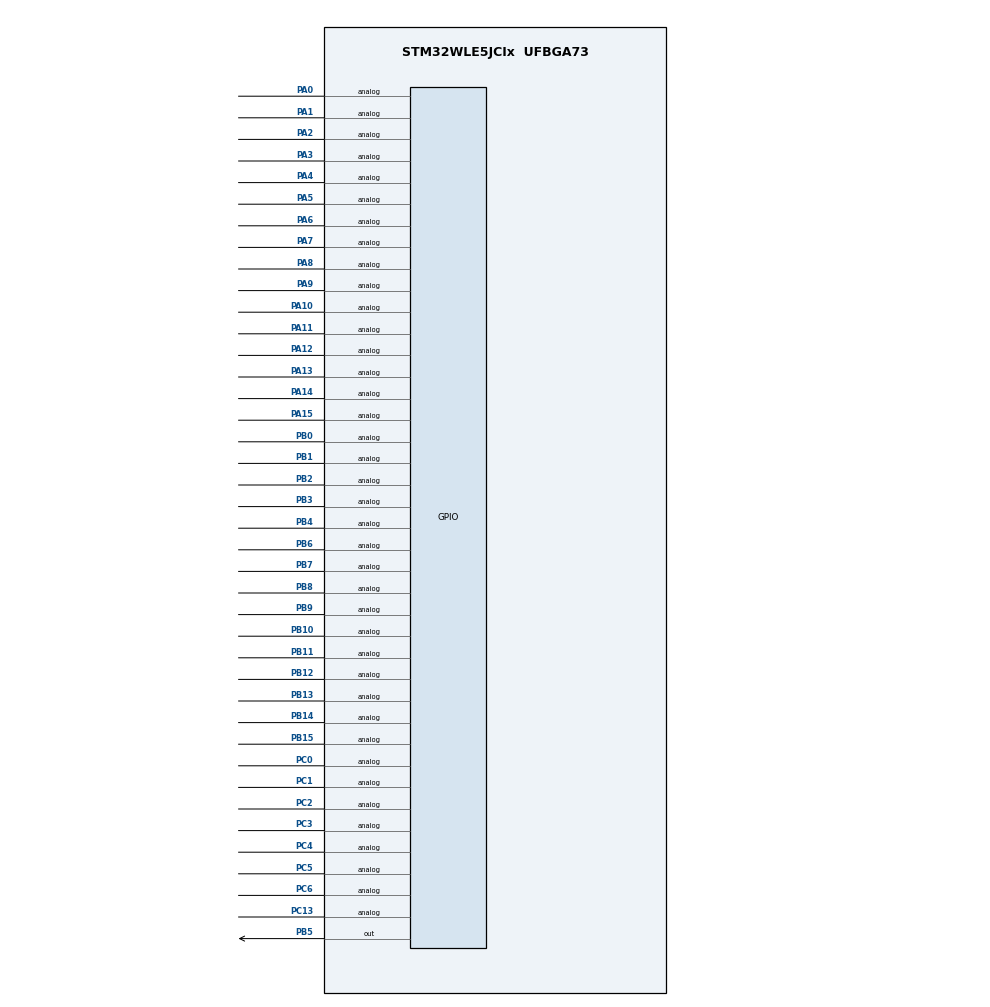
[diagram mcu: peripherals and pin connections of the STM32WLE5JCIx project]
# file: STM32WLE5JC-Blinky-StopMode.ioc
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Mcu.Family=STM32WL
Mcu.Name=STM32WLE5JCIx
Mcu.Package=UFBGA73
NVIC.PriorityGroup=NVIC_PRIORITYGROUP_4
NVIC.RTC_WKUP_IRQn=true\:0\:0\:false\:false\:true\:true\:true
PA0.Signal=GPIO_Analog
PA1.Signal=GPIO_Analog
PA10.Signal=GPIO_Analog
PA11.Signal=GPIO_Analog
PA12.Signal=GPIO_Analog
PA13.Signal=GPIO_Analog
PA14.Signal=GPIO_Analog
PA15.Signal=GPIO_Analog
PA2.Signal=GPIO_Analog
PA3.Signal=GPIO_Analog
PA4.Signal=GPIO_Analog
PA5.Signal=GPIO_Analog
PA6.Signal=GPIO_Analog
PA7.Signal=GPIO_Analog
PA8.Signal=GPIO_Analog
PA9.Signal=GPIO_Analog
PB0-VDD_TCXO.Signal=GPIO_Analog
PB1.Signal=GPIO_Analog
PB10.Signal=GPIO_Analog
PB11.Signal=GPIO_Analog
PB12.Signal=GPIO_Analog
PB13.Signal=GPIO_Analog
PB14.Signal=GPIO_Analog
PB15.Signal=GPIO_Analog
PB2.Signal=GPIO_Analog
PB3.Signal=GPIO_Analog
PB4.Signal=GPIO_Analog
PB5.GPIO_PuPd=GPIO_PULLUP
PB5.Signal=GPIO_Output
PB6.Signal=GPIO_Analog
PB7.Signal=GPIO_Analog
PB8.Signal=GPIO_Analog
PB9.Signal=GPIO_Analog
PC0.Signal=GPIO_Analog
PC1.Signal=GPIO_Analog
PC13.Signal=GPIO_Analog
PC14-OSC32_IN.Mode=LSE-External-Oscillator
PC14-OSC32_IN.Signal=RCC_OSC32_IN
PC15-OSC32_OUT.Mode=LSE-External-Oscillator
PC15-OSC32_OUT.Signal=RCC_OSC32_OUT
PC2.Signal=GPIO_Analog
PC3.Signal=GPIO_Analog
PC4.Signal=GPIO_Analog
PC5.Signal=GPIO_Analog
PC6.Signal=GPIO_Analog
ProjectManager.HeapSize=0x200
ProjectManager.StackSize=0x400
ProjectManager.TargetToolchain=STM32CubeIDE
RCC.AHBFreq_Value=48000000
RCC.APB1Freq_Value=48000000
RCC.APB1TimFreq_Value=48000000
RCC.APB2Freq_Value=48000000
RCC.APB2TimFreq_Value=48000000
RCC.APB3Freq_Value=48000000
RCC.CortexFreq_Value=48000000
RCC.HCLKFreq_Value=48000000
RCC.HSE_VALUE=8000000
RCC.HSI_VALUE=16000000
RCC.LSE_VALUE=32768
RCC.MSIClockRange=RCC_MSIRANGE_11
RCC.RTCClockSelection=RCC_RTCCLKSOURCE_LSE
RCC.SYSCLKFreq_VALUE=48000000
RCC.VCOOutputFreq_Value=384000000
VP_RTC_VS_RTC_Activate.Mode=RTC_Enabled
VP_RTC_VS_RTC_WakeUp_intern.Mode=WakeUp
board=custom

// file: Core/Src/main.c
/* USER CODE BEGIN Header */
/**
  ******************************************************************************
  * @file           : main.c
  * @brief          : Main program body
  ******************************************************************************
  * @attention
  *
  * <h2><center>&copy; Copyright (c) 2021 STMicroelectronics.
  * All rights reserved.</center></h2>
  *
  * This software component is licensed by ST under BSD 3-Clause license,
  * the "License"; You may not use this file except in compliance with the
  * License. You may obtain a copy of the License at:
  *                        opensource.org/licenses/BSD-3-Clause
  *
  ******************************************************************************
  */
/* USER CODE END Header */
#include "main.h"

RTC_HandleTypeDef hrtc;

void SystemClock_Config(void);
static void MX_RTC_Init(void);
static void MX_GPIO_Init(void);

int main(void)
{

  /* MCU Configuration--------------------------------------------------------*/

  /* Reset of all peripherals, Initializes the Flash interface and the Systick. */
  HAL_Init();

  /* Configure the system clock */
  SystemClock_Config();

  /* Initialize all configured peripherals */
  MX_RTC_Init();
  MX_GPIO_Init();
  /* USER CODE BEGIN 2 */
  // prevent firing too early
  HAL_RTCEx_DeactivateWakeUpTimer(&hrtc);
  HAL_GPIO_WritePin(GPIOB, GPIO_PIN_5, GPIO_PIN_SET);
  /* USER CODE END 2 */

  /* Infinite loop */
  /* USER CODE BEGIN WHILE */
  while (1)
  {
	  // 4 "blinks"
	  for (int i=0; i< 8; i++)
	  {
		  HAL_GPIO_TogglePin(GPIOB, GPIO_PIN_5);
		  HAL_Delay(200);
	  }
	  // prepare wakeup timer, 10secs
	  if (HAL_RTCEx_SetWakeUpTimer_IT(&hrtc, 0x4E20, RTC_WAKEUPCLOCK_RTCCLK_DIV16, 0) != HAL_OK)
	  {
	    Error_Handler();
	  }
	  // stop ticks and fall asleep
	  HAL_SuspendTick();
	  HAL_PWREx_EnterSTOP2Mode(PWR_STOPENTRY_WFI);

	  // (ー。ー) zzz (ー。ー) zzz (ー。ー) zzz

	  // restore clock and ticks
	  SystemClock_Config();
	  HAL_ResumeTick();
	  // deactivate RTC wake up
	  HAL_RTCEx_DeactivateWakeUpTimer(&hrtc);
    /* USER CODE END WHILE */

  }
}

void SystemClock_Config(void)
{
  RCC_OscInitTypeDef RCC_OscInitStruct = {0};
  RCC_ClkInitTypeDef RCC_ClkInitStruct = {0};

  /** Configure LSE Drive Capability
  */
  HAL_PWR_EnableBkUpAccess();
  __HAL_RCC_LSEDRIVE_CONFIG(RCC_LSEDRIVE_LOW);
  /** Configure the main internal regulator output voltage
  */
  __HAL_PWR_VOLTAGESCALING_CONFIG(PWR_REGULATOR_VOLTAGE_SCALE1);
  /** Initializes the CPU, AHB and APB busses clocks
  */
  RCC_OscInitStruct.OscillatorType = RCC_OSCILLATORTYPE_LSE|RCC_OSCILLATORTYPE_MSI;
  RCC_OscInitStruct.LSEState = RCC_LSE_ON;
  RCC_OscInitStruct.MSIState = RCC_MSI_ON;
  RCC_OscInitStruct.MSICalibrationValue = RCC_MSICALIBRATION_DEFAULT;
  RCC_OscInitStruct.MSIClockRange = RCC_MSIRANGE_11;
  RCC_OscInitStruct.PLL.PLLState = RCC_PLL_NONE;
  if (HAL_RCC_OscConfig(&RCC_OscInitStruct) != HAL_OK)
  {
    Error_Handler();
  }
  /** Configure the SYSCLKSource, HCLK, PCLK1 and PCLK2 clocks dividers
  */
  RCC_ClkInitStruct.ClockType = RCC_CLOCKTYPE_HCLK3|RCC_CLOCKTYPE_HCLK
                              |RCC_CLOCKTYPE_SYSCLK|RCC_CLOCKTYPE_PCLK1
                              |RCC_CLOCKTYPE_PCLK2;
  RCC_ClkInitStruct.SYSCLKSource = RCC_SYSCLKSOURCE_MSI;
  RCC_ClkInitStruct.AHBCLKDivider = RCC_SYSCLK_DIV1;
  RCC_ClkInitStruct.APB1CLKDivider = RCC_HCLK_DIV1;
  RCC_ClkInitStruct.APB2CLKDivider = RCC_HCLK_DIV1;
  RCC_ClkInitStruct.AHBCLK3Divider = RCC_SYSCLK_DIV1;

  if (HAL_RCC_ClockConfig(&RCC_ClkInitStruct, FLASH_LATENCY_2) != HAL_OK)
  {
    Error_Handler();
  }
}

static void MX_RTC_Init(void)
{

  /** Initialize RTC Only
  */
  hrtc.Instance = RTC;
  hrtc.Init.HourFormat = RTC_HOURFORMAT_24;
  hrtc.Init.AsynchPrediv = 127;
  hrtc.Init.SynchPrediv = 255;
  hrtc.Init.OutPut = RTC_OUTPUT_DISABLE;
  hrtc.Init.OutPutRemap = RTC_OUTPUT_REMAP_NONE;
  hrtc.Init.OutPutPolarity = RTC_OUTPUT_POLARITY_HIGH;
  hrtc.Init.OutPutType = RTC_OUTPUT_TYPE_OPENDRAIN;
  hrtc.Init.OutPutPullUp = RTC_OUTPUT_PULLUP_NONE;
  hrtc.Init.BinMode = RTC_BINARY_NONE;
  if (HAL_RTC_Init(&hrtc) != HAL_OK)
  {
    Error_Handler();
  }
  /** Enable the WakeUp
  */
  if (HAL_RTCEx_SetWakeUpTimer_IT(&hrtc, 0, RTC_WAKEUPCLOCK_RTCCLK_DIV16, 0) != HAL_OK)
  {
    Error_Handler();
  }

}

static void MX_GPIO_Init(void)
{
  GPIO_InitTypeDef GPIO_InitStruct = {0};

  /* GPIO Ports Clock Enable */
  __HAL_RCC_GPIOA_CLK_ENABLE();
  __HAL_RCC_GPIOB_CLK_ENABLE();
  __HAL_RCC_GPIOC_CLK_ENABLE();

  /*Configure GPIO pin Output Level */
  HAL_GPIO_WritePin(GPIOB, GPIO_PIN_5, GPIO_PIN_RESET);

  /*Configure GPIO pins : PA14 PA12 PA15 PA13
                           PA11 PA10 PA0 PA9
                           PA6 PA1 PA3 PA2
                           PA7 PA4 PA5 PA8 */
  GPIO_InitStruct.Pin = GPIO_PIN_14|GPIO_PIN_12|GPIO_PIN_15|GPIO_PIN_13
                          |GPIO_PIN_11|GPIO_PIN_10|GPIO_PIN_0|GPIO_PIN_9
                          |GPIO_PIN_6|GPIO_PIN_1|GPIO_PIN_3|GPIO_PIN_2
                          |GPIO_PIN_7|GPIO_PIN_4|GPIO_PIN_5|GPIO_PIN_8;
  GPIO_InitStruct.Mode = GPIO_MODE_ANALOG;
  GPIO_InitStruct.Pull = GPIO_NOPULL;
  HAL_GPIO_Init(GPIOA, &GPIO_InitStruct);

  /*Configure GPIO pins : PB15 PB3 PB4 PB7
                           PB9 PB14 PB8 PB13
                           PB2 PB6 PB12 PB1
                           PB0 PB11 PB10 */
  GPIO_InitStruct.Pin = GPIO_PIN_15|GPIO_PIN_3|GPIO_PIN_4|GPIO_PIN_7
                          |GPIO_PIN_9|GPIO_PIN_14|GPIO_PIN_8|GPIO_PIN_13
                          |GPIO_PIN_2|GPIO_PIN_6|GPIO_PIN_12|GPIO_PIN_1
                          |GPIO_PIN_0|GPIO_PIN_11|GPIO_PIN_10;
  GPIO_InitStruct.Mode = GPIO_MODE_ANALOG;
  GPIO_InitStruct.Pull = GPIO_NOPULL;
  HAL_GPIO_Init(GPIOB, &GPIO_InitStruct);

  /*Configure GPIO pins : PC13 PC2 PC3 PC5
                           PC1 PC0 PC4 PC6 */
  GPIO_InitStruct.Pin = GPIO_PIN_13|GPIO_PIN_2|GPIO_PIN_3|GPIO_PIN_5
                          |GPIO_PIN_1|GPIO_PIN_0|GPIO_PIN_4|GPIO_PIN_6;
  GPIO_InitStruct.Mode = GPIO_MODE_ANALOG;
  GPIO_InitStruct.Pull = GPIO_NOPULL;
  HAL_GPIO_Init(GPIOC, &GPIO_InitStruct);

  /*Configure GPIO pin : PB5 */
  GPIO_InitStruct.Pin = GPIO_PIN_5;
  GPIO_InitStruct.Mode = GPIO_MODE_OUTPUT_PP;
  GPIO_InitStruct.Pull = GPIO_PULLUP;
  GPIO_InitStruct.Speed = GPIO_SPEED_FREQ_LOW;
  HAL_GPIO_Init(GPIOB, &GPIO_InitStruct);

}

void Error_Handler(void)
{
  __disable_irq();
  while (1)
  {
  }
}

/************************ (C) COPYRIGHT STMicroelectronics *****END OF FILE****/
